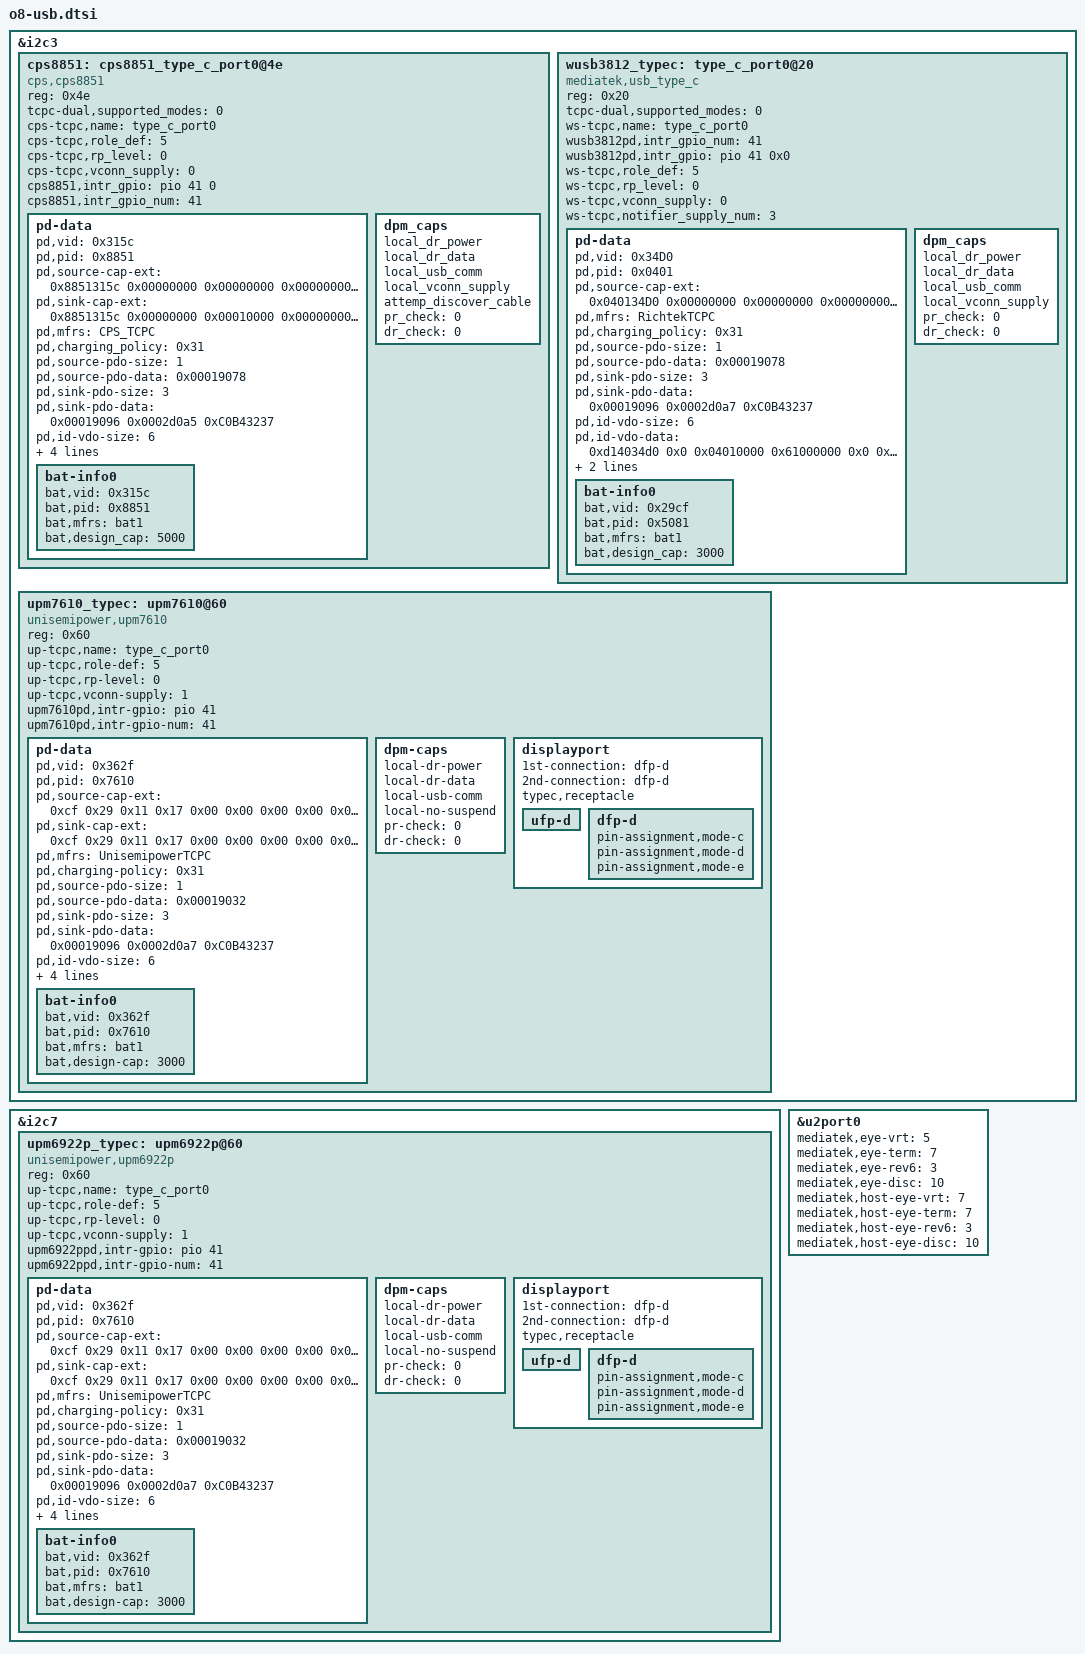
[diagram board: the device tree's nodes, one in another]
/* Note for tcpc data
* tcpc-dual,supported_modes : 0: dfp/ufp, 1: dfp, 2: ufp
* *-tcpc,role_def : 0: Unknown, 1: SNK, 2: SRC 3: DRP, 4: Try.SRC, 5: Try.SNK
* *-tcpc,rp_level: 0: Default, 1: 1.5, 2: 3.0
* *-tcpc,vconn_supply : 0: Never, 1: Always, 2: EMarkOnly, 3: StartOnly
* *-pd,charging_policy: VSAFE5V = 0, MAX_POWER = 1, CUSTOM = 2,MAX_POWER_LV = 0x21,
*                       MAX_POWER_LVIC = 0x31, MAX_POWER_HV = 0x41, MAX_POWER_HVIC = 0x51
* pd,sink-pdo-data: Fixed 5V, 500 mA <0x00019032>, Fixed 5V, 1A <0x00019064>, Fixed 5V, 2A <0x000190c8>
*                   Fixed 5V, 3A <0x0001912c>, Fixed 9V, 500 mA <0x0002d032>, Fixed 9V, 1A <0x0002d064>
*                   Fixed 9V, 2A <0x0002d0c8>, Fixed 9V, 3A <0x0002d12c>, Variable 5-9V, 1A <0x8642d064>
*                   Variable 5-9V, 2A <0x8642d0c8>, Variable 5-9V, 3A <0x8642d12c>, PPS 3V~5.9V, 3A <0xC0761E3C>
* No DP, host + device: pd,id-vdo-size = <6>;
*                       pd,id-vdo-data = <0xd14029cf 0x0 0x17110000
*                                         0x41800000 0x0 0x21800000>;
* With DP: pd,id-vdo-size = <6>;
*          pd,id-vdo-data = <0xd54029cf 0x0 0x17110000
*                            0x41800000 0x0 0x21800000>;
*/

&i2c3 {
    cps8851:cps8851_type_c_port0@4e{
        compatible = "cps,cps8851";
        reg = <0x4e>;
        status = "okay";
        tcpc-dual,supported_modes = <0>;
        cps-tcpc,name = "type_c_port0";
        cps-tcpc,role_def = <5>;
        cps-tcpc,rp_level = <0>;
        cps-tcpc,vconn_supply  = <0>;
        cps8851,intr_gpio = <&pio 41 0>;
        cps8851,intr_gpio_num = <41>;
        pd-data {
            pd,vid = <0x315c>;
            pd,pid = <0x8851>;
            pd,source-cap-ext = <0x8851315c 0x00000000 0x00000000
                        0x00000000 0x00000000 0x06000000 0x00000000>;
            pd,sink-cap-ext = <0x8851315c 0x00000000 0x00010000
                        0x00000000 0x05000000 0x0000000f>;
            pd,mfrs = "CPS_TCPC";
            pd,charging_policy= <0x31>;
            pd,source-pdo-size = <1>;
            pd,source-pdo-data = <0x00019078>;
            pd,sink-pdo-size = <3>;
            pd,sink-pdo-data = <0x00019096 0x0002d0a5 0xC0B43237>; // 9V1.65A
            pd,id-vdo-size = <6>;
            pd,id-vdo-data = <0xd140315c 0x0 0x88510000
                0x61000000 0x0 0x41000000>;

            bat,nr = <1>;
            pd,country_nr = <0>;

            bat-info0 {
                bat,vid = <0x315c>;
                bat,pid = <0x8851>;
                bat,mfrs = "bat1";
                bat,design_cap = <5000>;
            };
        };
        dpm_caps {
            local_dr_power;
            local_dr_data;
            local_usb_comm;
            local_vconn_supply;
            attemp_discover_cable;
            pr_check = <0>;
            dr_check = <0>;
        };
    };

    wusb3812_typec: type_c_port0@20 {
        reg = <0x20>;
        compatible = "mediatek,usb_type_c";
        status = "okay";
        tcpc-dual,supported_modes = <0>;
        ws-tcpc,name = "type_c_port0";
        wusb3812pd,intr_gpio_num = <41>;
        wusb3812pd,intr_gpio = <&pio 41 0x0>;
        ws-tcpc,role_def = <5>;
        ws-tcpc,rp_level = <0>;
        ws-tcpc,vconn_supply  = <0>;

        ws-tcpc,notifier_supply_num = <3>;

        pd-data {
            pd,vid = <0x34D0>;
            pd,pid = <0x0401>;
            pd,source-cap-ext = <0x040134D0 0x00000000 0x00000000
                            0x00000000 0x00000000 0x07010000 >;
            pd,mfrs = "RichtekTCPC";
            pd,charging_policy= <0x31>;

            pd,source-pdo-size = <1>;
            /*pd,source-pdo-data = <0x00019032>; kelong modify2*/
            pd,source-pdo-data = <0x00019078>;

            /*pd,sink-pdo-size = <2>;   kelong modify3
            pd,sink-pdo-data = <0x000190c8 0x0002d0a5> ; //5V,2A 9V,1.67A  */
            pd,sink-pdo-size = <3>;
            pd,sink-pdo-data = <0x00019096 0x0002d0a7 0xC0B43237>; // 9V1.65A
            /*pd,sink-pdo-data = <0x00019096 0x0002d0a5 0xC0B43237>; // 9V1.65A kelong modify4*/

            pd,id-vdo-size = <6>;
            pd,id-vdo-data = <0xd14034d0 0x0 0x04010000
                0x61000000 0x0 0x41000000>;
            bat,nr = <1>;
            pd,country_nr = <0>;

            bat-info0 {
                bat,vid = <0x29cf>;
                bat,pid = <0x5081>;
                bat,mfrs = "bat1";
                bat,design_cap = <3000>;
            };
        };
        dpm_caps {
            local_dr_power;
            local_dr_data;
            local_usb_comm;
            local_vconn_supply;
            pr_check = <0>; // 0: disable, 1: prefer_snk, 2: prefer_src
            dr_check = <0>; // 0: disable, 1: prefer_ufp, 2: prefer_dfp
        };
    };
	/*A06_V code for SR-AL7160V-01-135 by yexuedong at 20240827 start*/
    	upm7610_typec: upm7610@60 {
		compatible = "unisemipower,upm7610";
		reg = <0x60>;
		status = "okay";
		up-tcpc,name = "type_c_port0"; /* tcpc_device's name */
		up-tcpc,role-def = <5>; /* 0: Unknown, 1: SNK, 2: SRC */
					/* 3: DRP, 4: Try.SRC, 5: Try.SNK */
		up-tcpc,rp-level = <0>; /* 0: Default, 1: 1.5, 2: 3.0 */
		up-tcpc,vconn-supply = <1>;  /* 0: Never, 1: Always, */
					     /* 2: EMarkOnly, 3: StartOnly */
		upm7610pd,intr-gpio = <&pio 41 0x0>;
		upm7610pd,intr-gpio-num = <41>;
		pd-data {
			pd,vid = <0x362f>;
			pd,pid = <0x7610>;
			pd,source-cap-ext = /bits/ 8 <0xcf 0x29 0x11 0x17
						      0x00 0x00 0x00 0x00
						      0x00 0x00 0x00 0x00
						      0x00 0x00 0x00 0x00
						      0x00 0x00 0x00 0x00
						      0x00 0x00 0x01 0x02
						      0x00>;
			pd,sink-cap-ext = /bits/ 8 <0xcf 0x29 0x11 0x17
						    0x00 0x00 0x00 0x00
						    0x00 0x00 0x01 0x00
						    0x00 0x00 0x00 0x00
						    0x01 0x0b 0x01 0x0a
						    0x0a 0x00 0x00 0x00>;
			pd,mfrs = "UnisemipowerTCPC";
			/*
			 *	VSAFE5V = 0, MAX_POWER = 1, CUSTOM = 2,
			 *	MAX_POWER_LV = 0x21, MAX_POWER_LVIC = 0x31
			 *	MAX_POWER_HV = 0x41, MAX_POWER_HVIC = 0x51
			 */
			pd,charging-policy = <0x31>;
			/*
			 * Fixed 5V, 500 mA <0x00019032>
			 * Fixed 5V, 1A <0x00019064>
			 * Fixed 5V, 2A <0x000190c8>
			 * Fixed 5V, 3A <0x0001912c>
			 * Fixed 9V, 500 mA <0x0002d032>
			 * Fixed 9V, 1A <0x0002d064>
			 * Fixed 9V, 2A <0x0002d0c8>
			 * Fixed 9V, 3A <0x0002d12c>
			 * Variable 5-9V, 1A <0x8642d064>
			 * Variable 5-9V, 2A <0x8642d0c8>
			 * Variable 5-9V, 3A <0x8642d12c>
			 */
			pd,source-pdo-size = <1>;
			pd,source-pdo-data = <0x00019032>;
			/*A06_V code for SR-AL7160V-01-135 by yexuedong at 20240828 start*/
			pd,sink-pdo-size = <3>;
			pd,sink-pdo-data = <0x00019096 0x0002d0a7 0xC0B43237>;
			/*A06_V code for SR-AL7160V-01-135 by yexuedong at 20240828 end*/
			/*
			 * No DP, host + device
			 *	pd,id-vdo-size = <6>;
			 *	pd,id-vdo-data = <0xd14029cf 0x0 0x17110000
						  0x61000000 0x0 0x41000000>;
			 * With DP Sink capability
			 *	pd,id-vdo-size = <6>;
			 *	pd,id-vdo-data = <0xd54029cf 0x0 0x17110000
						  0x61000000 0x0 0x41000000>;
			 */
			pd,id-vdo-size = <6>;
			pd,id-vdo-data = <0xd14029cf 0x0 0x17110000
					  0x61000000 0x0 0x41000000>;
			bat,nr = <1>;
			pd,country-nr = <0>;
			bat-info0 {
				/*A06_V code for SR-AL7160V-01-135 by yexuedong at 20240828 start*/
				bat,vid = <0x362f>;
				bat,pid = <0x7610>;
				/*A06_V code for SR-AL7160V-01-135 by yexuedong at 20240828 end*/
				bat,mfrs = "bat1";
				bat,design-cap = <3000>;
			};
		};
		dpm-caps {
			local-dr-power;
			local-dr-data;
			// local-ext-power;
			local-usb-comm;
			// local-usb-suspend;
			// local-high-cap;
			// local-give-back;
			local-no-suspend;
			/* With DP Source capability */
			// attempt-enter-dp-mode;
			// attempt-discover-cable;
			// attempt-discover-id;
			// attempt-discover-svids;
			/* 0: disable, 1: prefer-snk, 2: prefer-src */
			pr-check = <0>;
			// pr-reject-as-source;
			// pr-reject-as-sink;
			// pr-check-gp-source;
			// pr-check-gp-sink;
			/* 0: disable, 1: prefer-ufp, 2: prefer-dfp */
			dr-check = <0>;
			// dr-reject-as-dfp;
			// dr-reject-as-ufp;
		};
		displayport {
			/* connection type = "both", "ufp-d", "dfp-d" */
			1st-connection = "dfp-d";
			2nd-connection = "dfp-d";
			// usbr20-not-used;
			typec,receptacle;
			ufp-d {
				// pin-assignment,mode-c;
				// pin-assignment,mode-d;
				// pin-assignment,mode-e;
			};
			dfp-d {
				pin-assignment,mode-c;
				pin-assignment,mode-d;
				pin-assignment,mode-e;
			};
		};
	};
	/*A06_V code for SR-AL7160V-01-135 by yexuedong at 20240827 end*/
};

&i2c7{
	/*A06_V code for SR-AL7160V-01-133 by yexuedong at 20240829 start*/
	upm6922p_typec: upm6922p@60 {
		compatible = "unisemipower,upm6922p";
		reg = <0x60>;
		status = "okay";
		up-tcpc,name = "type_c_port0"; /* tcpc_device's name */
		up-tcpc,role-def = <5>; /* 0: Unknown, 1: SNK, 2: SRC */
					/* 3: DRP, 4: Try.SRC, 5: Try.SNK */
		up-tcpc,rp-level = <0>; /* 0: Default, 1: 1.5, 2: 3.0 */
		up-tcpc,vconn-supply = <1>;  /* 0: Never, 1: Always, */
					     /* 2: EMarkOnly, 3: StartOnly */
		upm6922ppd,intr-gpio = <&pio 41 0x0>;
		upm6922ppd,intr-gpio-num = <41>;
		pd-data {
			pd,vid = <0x362f>;
			pd,pid = <0x7610>;
			pd,source-cap-ext = /bits/ 8 <0xcf 0x29 0x11 0x17
						      0x00 0x00 0x00 0x00
						      0x00 0x00 0x00 0x00
						      0x00 0x00 0x00 0x00
						      0x00 0x00 0x00 0x00
						      0x00 0x00 0x01 0x02
						      0x00>;
			pd,sink-cap-ext = /bits/ 8 <0xcf 0x29 0x11 0x17
						    0x00 0x00 0x00 0x00
						    0x00 0x00 0x01 0x00
						    0x00 0x00 0x00 0x00
						    0x01 0x0b 0x01 0x0a
						    0x0a 0x00 0x00 0x00>;
			pd,mfrs = "UnisemipowerTCPC";
			/*
			 *	VSAFE5V = 0, MAX_POWER = 1, CUSTOM = 2,
			 *	MAX_POWER_LV = 0x21, MAX_POWER_LVIC = 0x31
			 *	MAX_POWER_HV = 0x41, MAX_POWER_HVIC = 0x51
			 */
			pd,charging-policy = <0x31>;
			/*
			 * Fixed 5V, 500 mA <0x00019032>
			 * Fixed 5V, 1A <0x00019064>
			 * Fixed 5V, 2A <0x000190c8>
			 * Fixed 5V, 3A <0x0001912c>
			 * Fixed 9V, 500 mA <0x0002d032>
			 * Fixed 9V, 1A <0x0002d064>
			 * Fixed 9V, 2A <0x0002d0c8>
			 * Fixed 9V, 3A <0x0002d12c>
			 * Variable 5-9V, 1A <0x8642d064>
			 * Variable 5-9V, 2A <0x8642d0c8>
			 * Variable 5-9V, 3A <0x8642d12c>
			 */
			pd,source-pdo-size = <1>;
			pd,source-pdo-data = <0x00019032>;
			/*A06_V code for SR-AL7160V-01-135 by yexuedong at 20240828 start*/
			pd,sink-pdo-size = <3>;
			pd,sink-pdo-data = <0x00019096 0x0002d0a7 0xC0B43237>;
			/*A06_V code for SR-AL7160V-01-135 by yexuedong at 20240828 end*/
			/*
			 * No DP, host + device
			 *	pd,id-vdo-size = <6>;
			 *	pd,id-vdo-data = <0xd14029cf 0x0 0x17110000
						  0x61000000 0x0 0x41000000>;
			 * With DP Sink capability
			 *	pd,id-vdo-size = <6>;
			 *	pd,id-vdo-data = <0xd54029cf 0x0 0x17110000
						  0x61000000 0x0 0x41000000>;
			 */
			pd,id-vdo-size = <6>;
			pd,id-vdo-data = <0xd14029cf 0x0 0x17110000
					  0x61000000 0x0 0x41000000>;
			bat,nr = <1>;
			pd,country-nr = <0>;
			bat-info0 {
				/*A06_V code for SR-AL7160V-01-135 by yexuedong at 20240828 start*/
				bat,vid = <0x362f>;
				bat,pid = <0x7610>;
				/*A06_V code for SR-AL7160V-01-135 by yexuedong at 20240828 end*/
				bat,mfrs = "bat1";
				bat,design-cap = <3000>;
			};
		};
		dpm-caps {
			local-dr-power;
			local-dr-data;
			// local-ext-power;
			local-usb-comm;
			// local-usb-suspend;
			// local-high-cap;
			// local-give-back;
			local-no-suspend;
			/* With DP Source capability */
			// attempt-enter-dp-mode;
			// attempt-discover-cable;
			// attempt-discover-id;
			// attempt-discover-svids;
			/* 0: disable, 1: prefer-snk, 2: prefer-src */
			pr-check = <0>;
			// pr-reject-as-source;
			// pr-reject-as-sink;
			// pr-check-gp-source;
			// pr-check-gp-sink;
			/* 0: disable, 1: prefer-ufp, 2: prefer-dfp */
			dr-check = <0>;
			// dr-reject-as-dfp;
			// dr-reject-as-ufp;
		};
		displayport {
			/* connection type = "both", "ufp-d", "dfp-d" */
			1st-connection = "dfp-d";
			2nd-connection = "dfp-d";
			// usbr20-not-used;
			typec,receptacle;
			ufp-d {
				// pin-assignment,mode-c;
				// pin-assignment,mode-d;
				// pin-assignment,mode-e;
			};
			dfp-d {
				pin-assignment,mode-c;
				pin-assignment,mode-d;
				pin-assignment,mode-e;
			};
		};
	};
	/*A06_V code for SR-AL7160V-01-133 by yexuedong at 20240829 end*/
};

&u2port0 {
    mediatek,eye-vrt = <5>; /* 0~7 */
    mediatek,eye-term = <7>; /* 0~7 */
    mediatek,eye-rev6 = <3>; /* 0~3 */
    mediatek,eye-disc = <10>; /* 0~8 */
    mediatek,host-eye-vrt = <7>; /* 0~7 */
    mediatek,host-eye-term = <7>; /* 0~7 */
    mediatek,host-eye-rev6 = <3>; /* 0~3 */
    mediatek,host-eye-disc = <10>; /* 0~8 */
};
